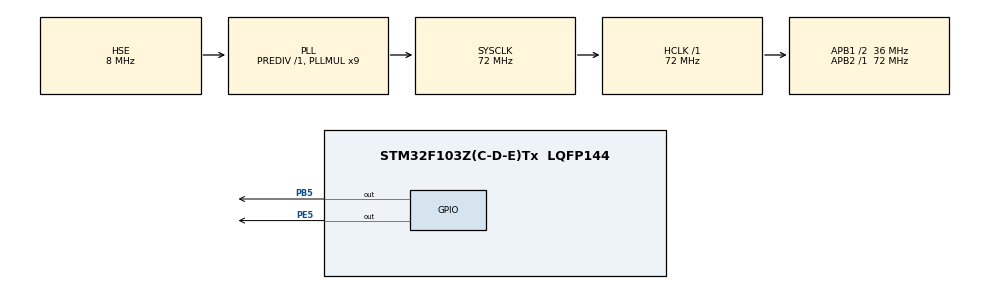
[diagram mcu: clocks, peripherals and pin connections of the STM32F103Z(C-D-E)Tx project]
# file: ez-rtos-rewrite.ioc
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Mcu.Family=STM32F1
Mcu.Name=STM32F103Z(C-D-E)Tx
Mcu.Package=LQFP144
NVIC.PriorityGroup=NVIC_PRIORITYGROUP_4
NVIC.TIM1_UP_IRQn=true\:0\:0\:false\:false\:true\:false\:true
NVIC.TimeBase=TIM1_UP_IRQn
NVIC.TimeBaseIP=TIM1
OSC_IN.Mode=HSE-External-Oscillator
OSC_IN.Signal=RCC_OSC_IN
OSC_OUT.Mode=HSE-External-Oscillator
OSC_OUT.Signal=RCC_OSC_OUT
PA13.Mode=JTAG_4_pins
PA13.Signal=SYS_JTMS-SWDIO
PA14.Mode=JTAG_4_pins
PA14.Signal=SYS_JTCK-SWCLK
PA15.Mode=JTAG_4_pins
PA15.Signal=SYS_JTDI
PB3.Mode=JTAG_4_pins
PB3.Signal=SYS_JTDO-TRACESWO
PB5.GPIO_Speed=GPIO_SPEED_FREQ_MEDIUM
PB5.PinState=GPIO_PIN_SET
PB5.Signal=GPIO_Output
PE5.GPIO_Speed=GPIO_SPEED_FREQ_MEDIUM
PE5.PinState=GPIO_PIN_SET
PE5.Signal=GPIO_Output
ProjectManager.HeapSize=0x200
ProjectManager.StackSize=0x400
ProjectManager.TargetToolchain=MDK-ARM V5.27
RCC.AHBFreq_Value=72000000
RCC.APB1CLKDivider=RCC_HCLK_DIV2
RCC.APB1Freq_Value=36000000
RCC.APB1TimFreq_Value=72000000
RCC.APB2Freq_Value=72000000
RCC.APB2TimFreq_Value=72000000
RCC.HCLKFreq_Value=72000000
RCC.PLLMUL=RCC_PLL_MUL9
RCC.PLLSourceVirtual=RCC_PLLSOURCE_HSE
RCC.SYSCLKFreq_VALUE=72000000
RCC.SYSCLKSource=RCC_SYSCLKSOURCE_PLLCLK
RCC.USBFreq_Value=72000000
VP_SYS_VS_tim1.Mode=TIM1
board=custom

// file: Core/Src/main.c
/* USER CODE BEGIN Header */
/**
  ******************************************************************************
  * @file           : main.c
  * @brief          : Main program body
  ******************************************************************************
  * @attention
  *
  * <h2><center>&copy; Copyright (c) 2022 STMicroelectronics.
  * All rights reserved.</center></h2>
  *
  * This software component is licensed by ST under BSD 3-Clause license,
  * the "License"; You may not use this file except in compliance with the
  * License. You may obtain a copy of the License at:
  *                        opensource.org/licenses/BSD-3-Clause
  *
  ******************************************************************************
  */
/* USER CODE END Header */
#include "main.h"

/* USER CODE BEGIN PV */
#define STACK_SIZE 256

stack_t stack_0[STACK_SIZE];
stack_t stack_1[STACK_SIZE];

#define DELAY_US 1000000

void task_blink_led_0() {
	int n = 0;
	for (;;) {
		n=(n==0)?1:0;
		if(n==0)
		{
			HAL_GPIO_WritePin(GPIOE, GPIO_PIN_5, GPIO_PIN_RESET);
		}
		else
		{
			HAL_GPIO_WritePin(GPIOE, GPIO_PIN_5, GPIO_PIN_SET);
		}
		sleep(DELAY_US);
	}
}

void task_blink_led_1() {
	int n = 0;
	for (;;) {
		n=(n==0)?1:0;
		if(n==0)
		{
			HAL_GPIO_WritePin(GPIOB, GPIO_PIN_5, GPIO_PIN_RESET);
		}
		else
		{
			HAL_GPIO_WritePin(GPIOB, GPIO_PIN_5, GPIO_PIN_SET);
		}
		sleep(DELAY_US);
	}
}

/* USER CODE END PV */

void SystemClock_Config(void);
static void MX_GPIO_Init(void);

int main(void)
{

  /* MCU Configuration--------------------------------------------------------*/

  /* Reset of all peripherals, Initializes the Flash interface and the Systick. */
  HAL_Init();

  /* Configure the system clock */
  SystemClock_Config();

  /* Initialize all configured peripherals */
  MX_GPIO_Init();
  /* USER CODE BEGIN 2 */

	os_init();

	create_task(task_blink_led_0, 0, stack_0, STACK_SIZE);
	create_task(task_blink_led_1, 0, stack_1, STACK_SIZE);

	os_start();

  /* USER CODE END 2 */

  /* Infinite loop */
  while (1)
  {

  }
}

void SystemClock_Config(void)
{
  RCC_OscInitTypeDef RCC_OscInitStruct = {0};
  RCC_ClkInitTypeDef RCC_ClkInitStruct = {0};

  /** Initializes the RCC Oscillators according to the specified parameters
  * in the RCC_OscInitTypeDef structure.
  */
  RCC_OscInitStruct.OscillatorType = RCC_OSCILLATORTYPE_HSE;
  RCC_OscInitStruct.HSEState = RCC_HSE_ON;
  RCC_OscInitStruct.HSEPredivValue = RCC_HSE_PREDIV_DIV1;
  RCC_OscInitStruct.HSIState = RCC_HSI_ON;
  RCC_OscInitStruct.PLL.PLLState = RCC_PLL_ON;
  RCC_OscInitStruct.PLL.PLLSource = RCC_PLLSOURCE_HSE;
  RCC_OscInitStruct.PLL.PLLMUL = RCC_PLL_MUL9;
  if (HAL_RCC_OscConfig(&RCC_OscInitStruct) != HAL_OK)
  {
    Error_Handler();
  }
  /** Initializes the CPU, AHB and APB buses clocks
  */
  RCC_ClkInitStruct.ClockType = RCC_CLOCKTYPE_HCLK|RCC_CLOCKTYPE_SYSCLK
                              |RCC_CLOCKTYPE_PCLK1|RCC_CLOCKTYPE_PCLK2;
  RCC_ClkInitStruct.SYSCLKSource = RCC_SYSCLKSOURCE_PLLCLK;
  RCC_ClkInitStruct.AHBCLKDivider = RCC_SYSCLK_DIV1;
  RCC_ClkInitStruct.APB1CLKDivider = RCC_HCLK_DIV2;
  RCC_ClkInitStruct.APB2CLKDivider = RCC_HCLK_DIV1;

  if (HAL_RCC_ClockConfig(&RCC_ClkInitStruct, FLASH_LATENCY_2) != HAL_OK)
  {
    Error_Handler();
  }
}

static void MX_GPIO_Init(void)
{
  GPIO_InitTypeDef GPIO_InitStruct = {0};

  /* GPIO Ports Clock Enable */
  __HAL_RCC_GPIOE_CLK_ENABLE();
  __HAL_RCC_GPIOA_CLK_ENABLE();
  __HAL_RCC_GPIOB_CLK_ENABLE();

  /*Configure GPIO pin Output Level */
  HAL_GPIO_WritePin(GPIOE, GPIO_PIN_5, GPIO_PIN_SET);

  /*Configure GPIO pin Output Level */
  HAL_GPIO_WritePin(GPIOB, GPIO_PIN_5, GPIO_PIN_SET);

  /*Configure GPIO pin : PE5 */
  GPIO_InitStruct.Pin = GPIO_PIN_5;
  GPIO_InitStruct.Mode = GPIO_MODE_OUTPUT_PP;
  GPIO_InitStruct.Pull = GPIO_NOPULL;
  GPIO_InitStruct.Speed = GPIO_SPEED_FREQ_MEDIUM;
  HAL_GPIO_Init(GPIOE, &GPIO_InitStruct);

  /*Configure GPIO pin : PB5 */
  GPIO_InitStruct.Pin = GPIO_PIN_5;
  GPIO_InitStruct.Mode = GPIO_MODE_OUTPUT_PP;
  GPIO_InitStruct.Pull = GPIO_NOPULL;
  GPIO_InitStruct.Speed = GPIO_SPEED_FREQ_MEDIUM;
  HAL_GPIO_Init(GPIOB, &GPIO_InitStruct);

}

 /**
  * @brief  Period elapsed callback in non blocking mode
  * @note   This function is called  when TIM1 interrupt took place, inside
  * HAL_TIM_IRQHandler(). It makes a direct call to HAL_IncTick() to increment
  * a global variable "uwTick" used as application time base.
  * @param  htim : TIM handle
  * @retval None
  */
void HAL_TIM_PeriodElapsedCallback(TIM_HandleTypeDef *htim)
{
  if (htim->Instance == TIM1) {
    HAL_IncTick();
  }
}

void Error_Handler(void)
{
  __disable_irq();
  while (1)
  {
  }
}

/************************ (C) COPYRIGHT STMicroelectronics *****END OF FILE****/
